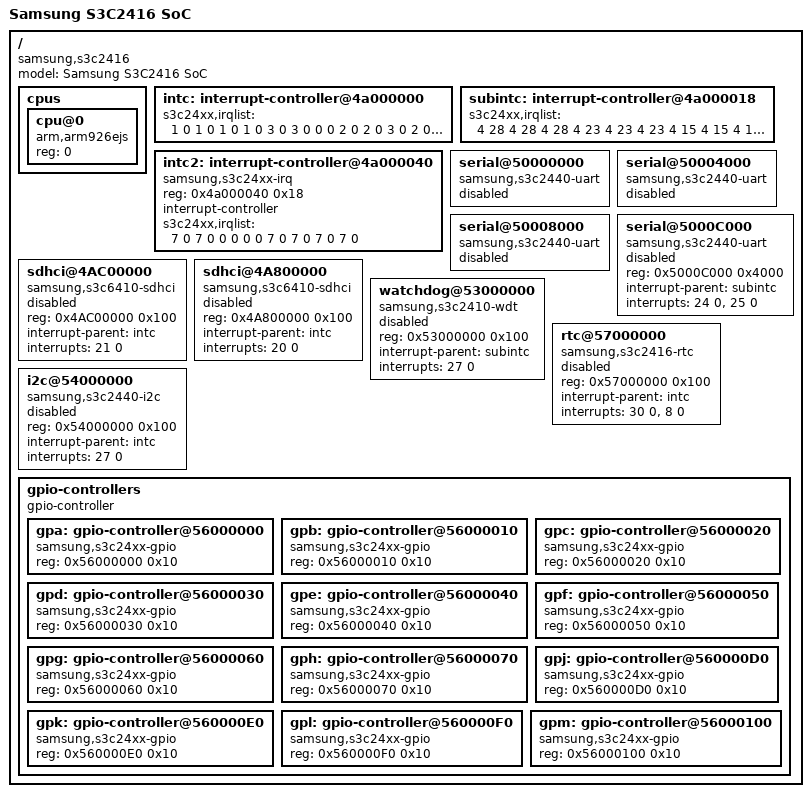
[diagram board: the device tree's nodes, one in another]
/*
 * Samsung's S3C2416 SoC device tree source
 *
 * Copyright (c) 2012 Heiko Stuebner <heiko@sntech.de>
 *
 * This program is free software; you can redistribute it and/or modify
 * it under the terms of the GNU General Public License version 2 as
 * published by the Free Software Foundation.
*/

/include/ "s3c24xx.dtsi"

/ {
	model = "Samsung S3C2416 SoC";
	compatible = "samsung,s3c2416";
//	interrupt-parent = <&intc>;

	cpus {
		#address-cells = <1>;
		#size-cells = <0>;

		cpu@0 {
			compatible = "arm,arm926ejs";
			reg = <0>;
		};
	};

	intc:interrupt-controller@4a000000 {
		s3c24xx,irqlist = <1 0 /* EINT0 */
				   1 0 /* EINT1 */
				   1 0 /* EINT2 */
				   1 0 /* EINT3 */
				   3 0 /* EINT4to7 */
				   3 0 /* EINT8to23 */
				   0 0 /* CAM on S3C2443/2450 */
				   2 0 /* nBATT_FLT */
				   2 0 /* TICK */
				   3 0 /* WDT/AC97 */
				   2 0 /* TIMER0 */
				   2 0 /* TIMER1 */
				   2 0 /* TIMER2 */
				   2 0 /* TIMER3 */
				   2 0 /* TIMER4 */
				   3 0 /* UART2 */
				   3 0 /* LCD */
				   3 0 /* DMA */
				   3 0 /* UART3 */
				   0 0 /* CFON on S3C2443/2450 */
				   2 0 /* SDI1 */
				   2 0 /* SDI0 */
				   2 0 /* SPI0 */
				   3 0 /* UART1 */
				   2 0 /* NAND */
				   2 0 /* USBD */
				   2 0 /* USBH */
				   2 0 /* IIC */
				   3 0 /* UART0 */
				   0 0 /* SPI1 on S3C243/2450 */
				   2 0 /* RTC */
				   3 0>; /* ADCPARENT */
	};

	subintc:interrupt-controller@4a000018 {
		s3c24xx,irqlist = <4 28 /* UART0-RX */
				   4 28 /* UART0-TX */
				   4 28 /* UART0-ERR */
				   4 23 /* UART1-RX */
				   4 23 /* UART1-TX */
				   4 23 /* UART1-ERR */
				   4 15 /* UART2-RX */
				   4 15 /* UART2-TX */
				   4 15 /* UART2-ERR */
				   5 31 /* TC */
				   5 31 /* ADC */
				   0 0 /* CAM_C S3C2450 (4,6) */
				   0 0 /* CAM_P S3C2450 */
				   0 0 /* reserved */
				   0 0 /* reserved */
				   4 16 /* LCD2 */
				   4 16 /* LCD3 */
				   4 16 /* LCD4 */
				   4 17 /* DMA0 */
				   4 17 /* DMA1 */
				   4 17 /* DMA2 */
				   4 17 /* DMA3 */
				   4 17 /* DMA4 */
				   4 17 /* DMA5 */
				   4 18 /* UART3-RX */
				   4 18 /* UART3-TX */
				   4 18 /* UART3-ERR */
				   4 9 /* WDT */
				   4 9>; /* AC97 */
	};

	intc2:interrupt-controller@4a000040 {
		compatible = "samsung,s3c24xx-irq";
		reg = <0x4a000040 0x18>;
		interrupt-controller;
		#interrupt-cells = <2>;

		s3c24xx,irqlist = <7 0 /* 2D */
				   7 0 /* IIC1 */
				   0 0 /* reserved */
				   0 0 /* reserved */
				   7 0 /* PCM0 */
				   7 0 /* PCM1 */
				   7 0 /* I2S0 */
				   7 0>; /* I2S1 */
	};

	serial@50000000 {
		compatible = "samsung,s3c2440-uart";
		status = "disabled";
	};

	serial@50004000 {
		compatible = "samsung,s3c2440-uart";
		status = "disabled";
	};

	serial@50008000 {
		compatible = "samsung,s3c2440-uart";
		status = "disabled";
	};

	serial@5000C000 {
		compatible = "samsung,s3c2440-uart";
		reg = <0x5000C000 0x4000>;
		interrupt-parent = <&subintc>;
		interrupts = <24 0>, <25 0>;
		status = "disabled";
	};

	sdhci@4AC00000 {
		compatible = "samsung,s3c6410-sdhci";
		reg = <0x4AC00000 0x100>;
		interrupt-parent = <&intc>;
		interrupts = <21 0>;
		status = "disabled";
	};

	sdhci@4A800000 {
		compatible = "samsung,s3c6410-sdhci";
		reg = <0x4A800000 0x100>;
		interrupt-parent = <&intc>;
		interrupts = <20 0>;
		status = "disabled";
	};

/* FIXME: where does this live (s3c24xx or s3c2416) */
	watchdog@53000000 {
		compatible = "samsung,s3c2410-wdt";
		reg = <0x53000000 0x100>;
		interrupt-parent = <&subintc>;
		interrupts = <27 0>;
		status = "disabled";
	};

	rtc@57000000 {
		compatible = "samsung,s3c2416-rtc";
		reg = <0x57000000 0x100>;
		interrupt-parent = <&intc>;
		interrupts = <30 0>, <8 0>;
		status = "disabled";
	};

	i2c@54000000 {
		compatible = "samsung,s3c2440-i2c";
		reg = <0x54000000 0x100>;
		interrupt-parent = <&intc>;
		interrupts = <27 0>;
		#address-cells = <1>;
		#size-cells = <0>;
		status = "disabled";
	};

	gpio-controllers {
		#address-cells = <1>;
		#size-cells = <1>;
		gpio-controller;
		ranges;

		gpa: gpio-controller@56000000 {
			compatible = "samsung,s3c24xx-gpio";
			reg = <0x56000000 0x10>;
			#gpio-cells = <3>;
		};

		gpb: gpio-controller@56000010 {
			compatible = "samsung,s3c24xx-gpio";
			reg = <0x56000010 0x10>;
			#gpio-cells = <3>;
		};

		gpc: gpio-controller@56000020 {
			compatible = "samsung,s3c24xx-gpio";
			reg = <0x56000020 0x10>;
			#gpio-cells = <3>;
		};

		gpd: gpio-controller@56000030 {
			compatible = "samsung,s3c24xx-gpio";
			reg = <0x56000030 0x10>;
			#gpio-cells = <3>;
		};

		gpe: gpio-controller@56000040 {
			compatible = "samsung,s3c24xx-gpio";
			reg = <0x56000040 0x10>;
			#gpio-cells = <3>;
		};

		gpf: gpio-controller@56000050 {
			compatible = "samsung,s3c24xx-gpio";
			reg = <0x56000050 0x10>;
			#gpio-cells = <3>;
		};

		gpg: gpio-controller@56000060 {
			compatible = "samsung,s3c24xx-gpio";
			reg = <0x56000060 0x10>;
			#gpio-cells = <3>;
		};

		gph: gpio-controller@56000070 {
			compatible = "samsung,s3c24xx-gpio";
			reg = <0x56000070 0x10>;
			#gpio-cells = <3>;
		};

		/* s3c2443 and later */
		gpj: gpio-controller@560000D0 {
			compatible = "samsung,s3c24xx-gpio";
			reg = <0x560000D0 0x10>;
			#gpio-cells = <3>;
		};

		gpk: gpio-controller@560000E0 {
			compatible = "samsung,s3c24xx-gpio";
			reg = <0x560000E0 0x10>;
			#gpio-cells = <3>;
		};

		gpl: gpio-controller@560000F0 {
			compatible = "samsung,s3c24xx-gpio";
			reg = <0x560000F0 0x10>;
			#gpio-cells = <3>;
		};

		gpm: gpio-controller@56000100 {
			compatible = "samsung,s3c24xx-gpio";
			reg = <0x56000100 0x10>;
			#gpio-cells = <3>;
		};
	};
};
